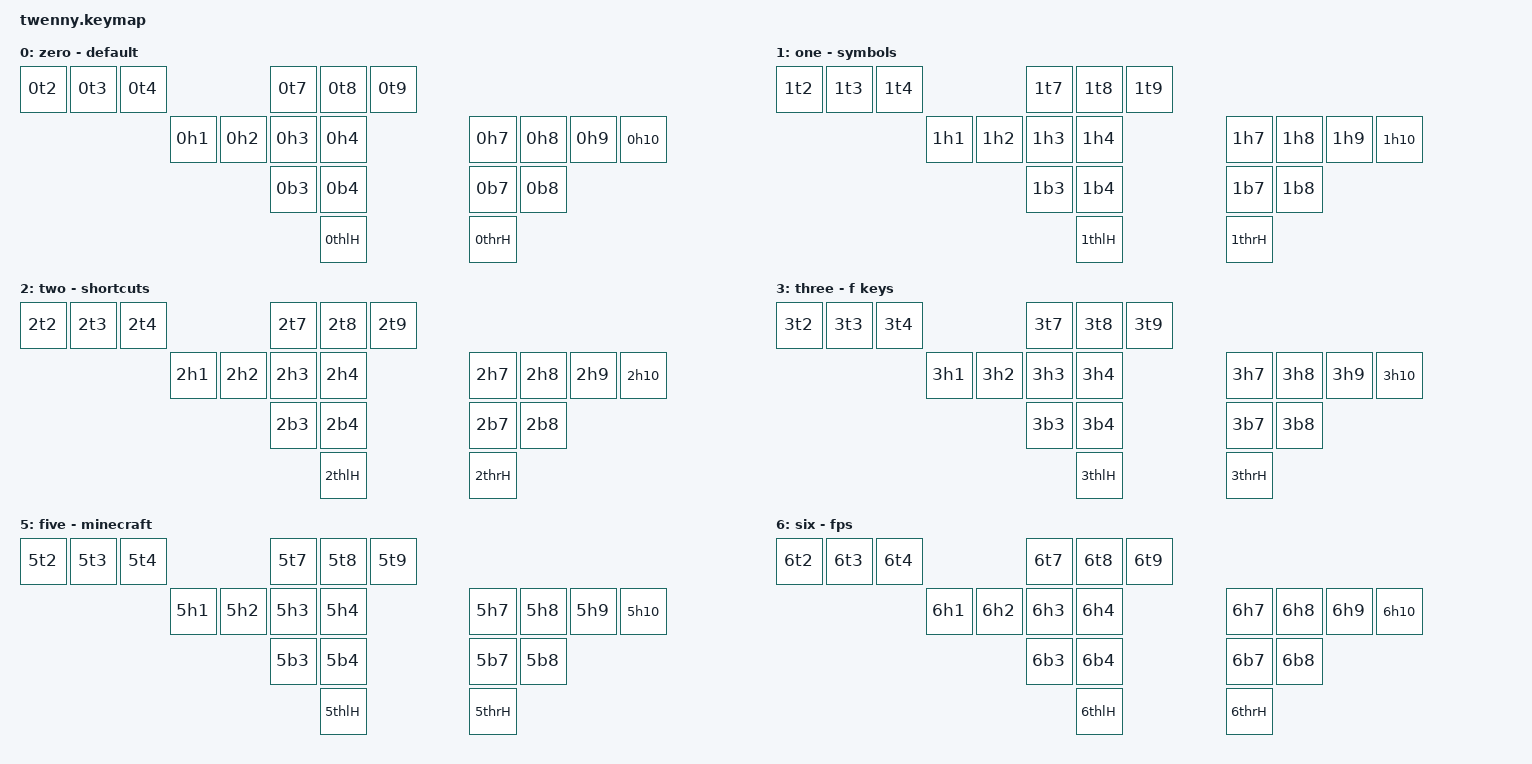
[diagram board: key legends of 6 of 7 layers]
#include "fingermap.h"
#include <behaviors/rgbled_widget.dtsi>

/ {
behaviors { // ---------------------------------------------------------------------------------
		hml: home_row_mod_l { hold-trigger-key-positions = < 0 1 2 6 7 8 9 14 15 18 >; 		  };
        hmr: home_row_mod_r { hold-trigger-key-positions = < 3 4 5 10 11 12 13 16 17 19 >; }; };
// ---------------------------------------------------------------------------------------------

keymap { compatible = "zmk,keymap";
		zero 	{ display-name = "zero - default"; // ----------
		bindings = < _0t2 _0t3 _0t4 		_0t7 _0t8 _0t9
				_0h1 _0h2 _0h3 _0h4 		_0h7 _0h8 _0h9 _0h10
				   		  _0b3 _0b4       	_0b7 _0b8
					         _0thlH			_0thrH 		   >; };
		one 	{ display-name = "one - symbols"; // -----------
		bindings = < _1t2 _1t3 _1t4 		_1t7 _1t8 _1t9
				_1h1 _1h2 _1h3 _1h4			_1h7 _1h8 _1h9 _1h10
					 	  _1b3 _1b4       	_1b7 _1b8
				         	 _1thlH	 		_1thrH 		   >; };
		two 	{ display-name = "two - shortcuts"; // ---------
		bindings = < _2t2 _2t3 _2t4 		_2t7 _2t8 _2t9
				_2h1 _2h2 _2h3 _2h4 		_2h7 _2h8 _2h9 _2h10
				   	 	  _2b3 _2b4         _2b7 _2b8
				         	 _2thlH	      	_2thrH 		   >; };
		three 	{ display-name = "three - f keys"; // ----------
		bindings = < _3t2 _3t3 _3t4 		_3t7 _3t8 _3t9
				_3h1 _3h2 _3h3 _3h4 		_3h7 _3h8 _3h9 _3h10
				   		  _3b3 _3b4         _3b7 _3b8
				         	 _3thlH	      	_3thrH 		   >; };
		four 	{ display-name = "four - qwer"; // -------------
		bindings = < _4t2 _4t3 _4t4 		_4t7 _4t8 _4t9
				_4h1 _4h2 _4h3 _4h4 		_4h7 _4h8 _4h9 _4h10
				   	 _4b2 _4b3 _4b4         _4b7 _4b8 _4b9
				         	 _4thlH	    	_4thrH 		   >; };
		five 	{ display-name = "five - minecraft"; // --------
		bindings = < _5t2 _5t3 _5t4 		_5t7 _5t8 _5t9
				_5h1 _5h2 _5h3 _5h4 		_5h7 _5h8 _5h9 _5h10
				   	 	  _5b3 _5b4         _5b7 _5b8
				         	 _5thlH	     	_5thrH 		   >; };
		six 	{ display-name = "six - fps"; // ---------------
		bindings = < _6t2 _6t3 _6t4 		_6t7 _6t8 _6t9
				_6h1 _6h2 _6h3 _6h4 		_6h7 _6h8 _6h9 _6h10
				   	 	  _6b3 _6b4         _6b7 _6b8
				         	 _6thlH			_6thrH 	 >; }; };

combos { compatible = "zmk,combos";

// alphas ----------------------------------------
		combo_qu {
			timeout-ms = <17>;
			key-positions = <16 17>;
			bindings = <&qumt Q 0>;
			layers = <0>;
		};
		combo_ze {
			timeout-ms = <30>;
			key-positions = <9 15>;
			bindings = <&zemt Z 0>;
			layers = <0>;
		};
		combo_v {
			timeout-ms = <30>;
			key-positions = <11 17>;
			bindings = <&kp V>;
			layers = <0>;
		};
		combo_w {
			timeout-ms = <30>;
			key-positions = <5 12>;
			bindings = <&kp W>;
			layers = <0>;
		};
		combo_p {
			timeout-ms = <30>;
			key-positions = <3 10>;
			bindings = <&kp P>;
			layers = <0>;
		};
		combo_g {
			timeout-ms = <30>;
			key-positions = <10 16>;
			bindings = <&kp K>;
			layers = <0>;
		};
		combo_b {
			timeout-ms = <30>;
			key-positions = <4 11>;
			bindings = <&kp B>;
			layers = <0>;
		};

// mods ------------------------------------------
		combo_enter {
			timeout-ms = <50>;
			key-positions = <9 10>;
			bindings = <&kp ENTER>;
			require-prior-idle-ms = <100>;
			layers = <0 1 2>;
		};
		combo_del { //del
			timeout-ms = <50>;
			key-positions = <6 7>;
			bindings = <LHO>;
			require-prior-idle-ms = <100>;
			layers = <0 1 2>;
		};
		combo_tab { //tab
			timeout-ms = <50>;
			key-positions = <0 2>;
			require-prior-idle-ms = <100>;
			bindings = <LUO>;
		};
		combo_esc { //esc
			timeout-ms = <50>;
			key-positions = <3 5>;
			require-prior-idle-ms = <100>;
			bindings = <RUO>;
		};
		combo_backspace { //back
			timeout-ms = <50>;
			key-positions = <12 13>;
			bindings = <&cbspc>;
			layers = <0 1 2>;
		};
		combo_left_back {
			timeout-ms = <50>;
			key-positions = <6 8>;
			bindings = <&cbspc>;
			layers = <0 1 2>;
		};
		combo_left_enter {
			timeout-ms = <50>;
			key-positions = <7 8>;
			bindings = <&kp ENTER>;
			require-prior-idle-ms = <100>;
			layers = <0 1 2>;
		};
		combo_left_esc {
			timeout-ms = <50>;
			key-positions = <0 9>;
			bindings = <&kp ESC>;
			require-prior-idle-ms = <100>;
			layers = <0 1 2>;
		};
		combo_right_del {
			timeout-ms = <50>;
			key-positions = <11 13>;
			bindings = <&kp DEL>;
			require-prior-idle-ms = <100>;
			layers = <0 1 2>;
		};
		combo_right_enter {
			timeout-ms = <50>;
			key-positions = <11 12>;
			bindings = <&kp ENTER>;
			require-prior-idle-ms = <100>;
			layers = <0 1 2>;
		};
		combo_right_tab {
			timeout-ms = <50>;
			key-positions = <5 10>;
			bindings = <&kp TAB>;
			require-prior-idle-ms = <100>;
			layers = <0 1 2>;
		};


// symbols ----------------------------------------

		combo_uni_up {
			timeout-ms = <50>;
			key-positions = <8 11>;
			bindings = <&uc 0x2191 0x2191>;
			require-prior-idle-ms = <100>;
			layers = <1>;
		};
		combo_uni_left {
			timeout-ms = <50>;
			key-positions = <7 10>;
			bindings = <&uc 0x2190 0x2190>;
			require-prior-idle-ms = <100>;
			layers = <1>;
		};
		combo_uni_down {
			timeout-ms = <50>;
			key-positions = <14 17>;
			bindings = <&uc 0x2193 0x2193>;
			require-prior-idle-ms = <100>;
			layers = <1>;
		};
		combo_uni_right {
			timeout-ms = <50>;
			key-positions = <9 12>;
			bindings = <&uc 0x2192 0x2192>;
			require-prior-idle-ms = <100>;
			layers = <1>;
		};

// arrows ----------------------------------------
		combo_up {
			timeout-ms = <50>;
			key-positions = <8 11>;
			bindings = <&kp UP>;
			layers = <0>;
			require-prior-idle-ms = <250>;
		};
		combo_left {
			timeout-ms = <50>;
			key-positions = <7 10>;
			bindings = <&kp LEFT>;
			layers = <0>;
			require-prior-idle-ms = <250>;
		};
		combo_down {
			timeout-ms = <50>;
			key-positions = <14 17>;
			bindings = <&kp DOWN>;
			layers = <0>;
			require-prior-idle-ms = <250>;
		};
		combo_right {
			timeout-ms = <50>;
			key-positions = <9 12>;
			bindings = <&kp RIGHT>;
			layers = <0>;
			require-prior-idle-ms = <250>;
		};

// layers ----------------------------------------
		combo_default_layer {
			timeout-ms = <50>;
			key-positions = <8 9 10 11>;
			bindings = <&to 0>;
		};
		combo_left_shortcut_layer {
			timeout-ms = <25>;
			key-positions = <6 9>;
			bindings = <&sl 5>;
			layers = <0 3>;
			require-prior-idle-ms = <250>;
		};
		combo_right_shortcut_layer {
			timeout-ms = <25>;
			key-positions = <10 13>;
			bindings = <&sl 5>;
			layers = <0 3>;
			require-prior-idle-ms = <250>;
		};
		combo_cad_layer {
			timeout-ms = <50>;
			key-positions = <6 7 8 15>;
			bindings = <&to 3>;
			require-prior-idle-ms = <100>;
			layers = <0>;
		};
		combo_fps_layer {
			timeout-ms = <50>;
			key-positions = <7 8 9>;
			bindings = <&to 6>;
			require-prior-idle-ms = <100>;
			layers = <0>;
		};
		combo_qwer_layer {
			timeout-ms = <50>;
			key-positions = <6 7 9 14>;
			bindings = <&to 7>;
			require-prior-idle-ms = <100>;
			layers = <0>;
		};
		combo_minecraft_layer {
			timeout-ms = <50>;
			key-positions = <1 6 7 9>;
			bindings = <&to 8>;
			require-prior-idle-ms = <100>;
			layers = <0>;
		};

// shortcut -------------------------------------- 
		combo_ctrl_shft_t {
			timeout-ms = <50>;
			key-positions = <2 9>;
			bindings = <&kp LC(LS(T))>;
			layers = <5>;
		};
		combo_ctrl_x {
			timeout-ms = <50>;
			key-positions = <9 15>;
			bindings = <&kp LC(X)>;
			layers = <5>;
		};

// special --------------------------------------- 
		combo_numword {
			timeout-ms = <50>;
			key-positions = <0 18>;
			bindings = <&num_word>;
			require-prior-idle-ms = <100>;
			layers = <0>;
		};
		combo_caps_word_lock {
			timeout-ms = <50>;
			key-positions = <5 19>;
			bindings = <&cmt CAPS 0>;
			require-prior-idle-ms = <100>;
			layers = <0>;
		};
		combo_right_stickyshift {
			timeout-ms = <30>;
			key-positions = <10 11>;
			bindings = <&sk LSHIFT>;
			layers = <0>;
		};
		combo_left_stickyshift {
			timeout-ms = <30>;
			key-positions = <8 9>;
			bindings = <&sk LSHIFT>;
			layers = <0>;
		};

// keyboard --------------------------------------
		combo_softoff_left {
			timeout-ms = <25>;
			key-positions = <6 7 8 9>;
			bindings = <&hw_soft_off>;
			require-prior-idle-ms = <100>;
			layers = <0>;
		};
		combo_softoff_right {
			timeout-ms = <25>;
			key-positions = <10 11 12 13>;
			bindings = <&hw_soft_off>;
			require-prior-idle-ms = <100>;
			layers = <0>;
		};

// cad -------------------------------------------
		combo_cad_numword {
			timeout-ms = <50>;
			key-positions = <0 18>;
			bindings = <&cad_num_word>;
			layers = <3>;
		};
		combo_p_cad {
			timeout-ms = <50>;
			key-positions = <0 7>;
			bindings = <&kp P>;
			layers = <3>;
		};
		combo_h_cad {
			timeout-ms = <50>;
			key-positions = <1 8>;
			bindings = <&kp H>;
			layers = <3>;
		};
		combo_i_cad {
			timeout-ms = <50>;
			key-positions = <2 9>;
			bindings = <&kp I>;
			layers = <3>;
		};
		combo_z_cad {
			timeout-ms = <50>;
			key-positions = <9 15>;
			bindings = <&kp Z>;
			layers = <3>;
		};
		combo_y_cad {
			timeout-ms = <50>;
			key-positions = <8 14>;
			bindings = <&kp Y>;
			layers = <3>;
		};

// game ------------------------------------------
		combo_1_game {
			timeout-ms = <75>;
			key-positions = <0 18>;
			bindings = <&kp N1>;
			layers = <6>;
		};
		combo_2_game {
			timeout-ms = <75>;
			key-positions = <1 18>;
			bindings = <&kp N2>;
			layers = <6>;
		};
		combo_3_game {
			timeout-ms = <75>;
			key-positions = <2 18>;
			bindings = <&kp N3>;
			layers = <6>;
		};
		combo_4_fps {
			timeout-ms = <50>;
			key-positions = <7 8 9>;
			bindings = <&kp N4>;
			layers = <6>;
		}; 
		combo_4_qwer {
			timeout-ms = <50>;
			key-positions = <1 2>;
			bindings = <&kp N4>;
			layers = <7>;
		};
		combo_b_g_game {
			timeout-ms = <50>;
			key-positions = <14 15>;
			bindings = <&mt B G>;
			layers = <6 7>;
		};
		combo_k_shift_fps {
			timeout-ms = <75>;
			key-positions = <6 18>;
			bindings = <&mt K LSHIFT>;
			layers = <6>;
		};
		combo_r_game {
			timeout-ms = <50>;
			key-positions = <1 2>;
			bindings = <&kp R>;
			layers = <6 8>;
		};
		combo_x_game {
			timeout-ms = <50>;
			key-positions = <0 1>;
			bindings = <&kp X>;
			layers = <6 7 8>;
		};
		combo_y_alt_qwer {
			timeout-ms = <50>;
			key-positions = <6 18>;
			bindings = <&mt LALT Y>;
			layers = <7>;
		};
		combo_esc_game {
			timeout-ms = <50>;
			key-positions = <0 1 2>;
			bindings = <&kp ESC>;
			layers = <6 8>;
		};
	};
};
